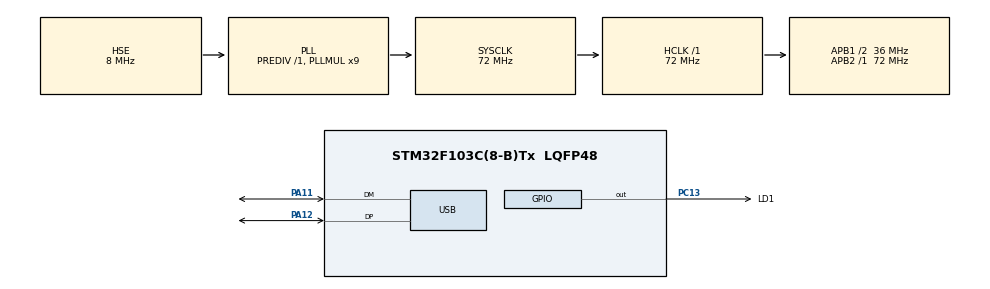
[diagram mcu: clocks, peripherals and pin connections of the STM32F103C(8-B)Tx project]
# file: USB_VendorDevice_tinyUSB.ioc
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Mcu.Family=STM32F1
Mcu.Name=STM32F103C(8-B)Tx
Mcu.Package=LQFP48
NVIC.PriorityGroup=NVIC_PRIORITYGROUP_4
NVIC.USB_HP_CAN1_TX_IRQn=true\:0\:0\:false\:false\:true\:true\:true
NVIC.USB_LP_CAN1_RX0_IRQn=true\:0\:0\:false\:false\:true\:true\:true
PA11.Mode=Device
PA11.Signal=USB_DM
PA12.Mode=Device
PA12.Signal=USB_DP
PA13.Mode=Serial_Wire
PA13.Signal=SYS_JTMS-SWDIO
PA14.Mode=Serial_Wire
PA14.Signal=SYS_JTCK-SWCLK
PC13-TAMPER-RTC.GPIO_Label=LD1
PC13-TAMPER-RTC.Signal=GPIO_Output
PD0-OSC_IN.Mode=HSE-External-Oscillator
PD0-OSC_IN.Signal=RCC_OSC_IN
PD1-OSC_OUT.Mode=HSE-External-Oscillator
PD1-OSC_OUT.Signal=RCC_OSC_OUT
ProjectManager.HeapSize=0x200
ProjectManager.StackSize=0x400
ProjectManager.TargetToolchain=STM32CubeIDE
RCC.AHBFreq_Value=72000000
RCC.APB1CLKDivider=RCC_HCLK_DIV2
RCC.APB1Freq_Value=36000000
RCC.APB1TimFreq_Value=72000000
RCC.APB2Freq_Value=72000000
RCC.APB2TimFreq_Value=72000000
RCC.HCLKFreq_Value=72000000
RCC.PLLMUL=RCC_PLL_MUL9
RCC.SYSCLKFreq_VALUE=72000000
RCC.SYSCLKSource=RCC_SYSCLKSOURCE_PLLCLK
RCC.USBFreq_Value=48000000
RCC.USBPrescaler=RCC_USBCLKSOURCE_PLL_DIV1_5
board=custom

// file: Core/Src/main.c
/* USER CODE BEGIN Header */
/**
  ******************************************************************************
  * @file           : main.c
  * @brief          : Main program body
  ******************************************************************************
  * @attention
  *
  * <h2><center>&copy; Copyright (c) 2021 STMicroelectronics.
  * All rights reserved.</center></h2>
  *
  * This software component is licensed by ST under BSD 3-Clause license,
  * the "License"; You may not use this file except in compliance with the
  * License. You may obtain a copy of the License at:
  *                        opensource.org/licenses/BSD-3-Clause
  *
  ******************************************************************************
  */
/* USER CODE END Header */
#include "main.h"
#include "usb.h"
#include "gpio.h"

/* USER CODE BEGIN Includes */
#include "usb_descriptors.h"
#include "tusb.h"
/* USER CODE END Includes */

void SystemClock_Config(void);
/* USER CODE BEGIN PFP */
void led_blinking_task(void);
void cdc_task(void);
void webserial_task(void);
/* USER CODE END PFP */

/* USER CODE BEGIN 0 */
#define URL  "example.tinyusb.org/webusb-serial/"

const tusb_desc_webusb_url_t desc_url =
{
  .bLength         = 3 + sizeof(URL) - 1,
  .bDescriptorType = 3, // WEBUSB URL type
  .bScheme         = 1, // 0: http, 1: https
  .url             = URL
};

static bool web_serial_connected = false;
/* USER CODE END 0 */

int main(void)
{

  /* MCU Configuration--------------------------------------------------------*/

  /* Reset of all peripherals, Initializes the Flash interface and the Systick. */
  HAL_Init();

  /* Configure the system clock */
  SystemClock_Config();

  /* Initialize all configured peripherals */
  MX_GPIO_Init();
  MX_USB_PCD_Init();
  /* USER CODE BEGIN 2 */
  tusb_init();
  /* USER CODE END 2 */

  /* Infinite loop */
  /* USER CODE BEGIN WHILE */
  while (1)
  {
	    tud_task(); // tinyusb device task
	    cdc_task();
	    webserial_task();
    /* USER CODE END WHILE */

  }
}

void SystemClock_Config(void)
{
  RCC_OscInitTypeDef RCC_OscInitStruct = {0};
  RCC_ClkInitTypeDef RCC_ClkInitStruct = {0};
  RCC_PeriphCLKInitTypeDef PeriphClkInit = {0};

  /** Initializes the RCC Oscillators according to the specified parameters
  * in the RCC_OscInitTypeDef structure.
  */
  RCC_OscInitStruct.OscillatorType = RCC_OSCILLATORTYPE_HSE;
  RCC_OscInitStruct.HSEState = RCC_HSE_ON;
  RCC_OscInitStruct.HSEPredivValue = RCC_HSE_PREDIV_DIV1;
  RCC_OscInitStruct.HSIState = RCC_HSI_ON;
  RCC_OscInitStruct.PLL.PLLState = RCC_PLL_ON;
  RCC_OscInitStruct.PLL.PLLSource = RCC_PLLSOURCE_HSE;
  RCC_OscInitStruct.PLL.PLLMUL = RCC_PLL_MUL9;
  if (HAL_RCC_OscConfig(&RCC_OscInitStruct) != HAL_OK)
  {
    Error_Handler();
  }
  /** Initializes the CPU, AHB and APB buses clocks
  */
  RCC_ClkInitStruct.ClockType = RCC_CLOCKTYPE_HCLK|RCC_CLOCKTYPE_SYSCLK
                              |RCC_CLOCKTYPE_PCLK1|RCC_CLOCKTYPE_PCLK2;
  RCC_ClkInitStruct.SYSCLKSource = RCC_SYSCLKSOURCE_PLLCLK;
  RCC_ClkInitStruct.AHBCLKDivider = RCC_SYSCLK_DIV1;
  RCC_ClkInitStruct.APB1CLKDivider = RCC_HCLK_DIV2;
  RCC_ClkInitStruct.APB2CLKDivider = RCC_HCLK_DIV1;

  if (HAL_RCC_ClockConfig(&RCC_ClkInitStruct, FLASH_LATENCY_2) != HAL_OK)
  {
    Error_Handler();
  }
  PeriphClkInit.PeriphClockSelection = RCC_PERIPHCLK_USB;
  PeriphClkInit.UsbClockSelection = RCC_USBCLKSOURCE_PLL_DIV1_5;
  if (HAL_RCCEx_PeriphCLKConfig(&PeriphClkInit) != HAL_OK)
  {
    Error_Handler();
  }
}

/* USER CODE BEGIN 4 */
// send characters to both CDC and WebUSB
void echo_all(uint8_t buf[], uint32_t count)
{
  // echo to web serial
  if ( web_serial_connected )
  {
    tud_vendor_write(buf, count);
  }

  // echo to cdc
  if ( tud_cdc_connected() )
  {
    for(uint32_t i=0; i<count; i++)
    {
      tud_cdc_write_char(buf[i]);

//      if ( buf[i] == '\r' ) tud_cdc_write_char('\n');
    }
    tud_cdc_write_flush();
  }
}

//--------------------------------------------------------------------+
// Device callbacks
//--------------------------------------------------------------------+

// Invoked when device is mounted
void tud_mount_cb(void)
{

}

// Invoked when device is unmounted
void tud_umount_cb(void)
{

}

// Invoked when usb bus is suspended
// remote_wakeup_en : if host allow us  to perform remote wakeup
// Within 7ms, device must draw an average of current less than 2.5 mA from bus
void tud_suspend_cb(bool remote_wakeup_en)
{
  (void) remote_wakeup_en;

}

// Invoked when usb bus is resumed
void tud_resume_cb(void)
{

}

//--------------------------------------------------------------------+
// WebUSB use vendor class
//--------------------------------------------------------------------+

// Invoked when a control transfer occurred on an interface of this class
// Driver response accordingly to the request and the transfer stage (setup/data/ack)
// return false to stall control endpoint (e.g unsupported request)
bool tud_vendor_control_xfer_cb(uint8_t rhport, uint8_t stage, tusb_control_request_t const * request)
{
  // nothing to with DATA & ACK stage
  if (stage != CONTROL_STAGE_SETUP) return true;

  switch (request->bmRequestType_bit.type)
  {
    case TUSB_REQ_TYPE_VENDOR:
      switch (request->bRequest)
      {
        case VENDOR_REQUEST_WEBUSB:
          // match vendor request in BOS descriptor
          // Get landing page url
          return tud_control_xfer(rhport, request, (void*)(uintptr_t) &desc_url, desc_url.bLength);

        case VENDOR_REQUEST_MICROSOFT:
          if ( request->wIndex == 7 )
          {
            // Get Microsoft OS 2.0 compatible descriptor
            uint16_t total_len;
            memcpy(&total_len, desc_ms_os_20+8, 2);

            return tud_control_xfer(rhport, request, (void*)(uintptr_t) desc_ms_os_20, total_len);
          }else
          {
            return false;
          }

        default: break;
      }
    break;

    case TUSB_REQ_TYPE_CLASS:
      if (request->bRequest == 0x22)
      {
        // Webserial simulate the CDC_REQUEST_SET_CONTROL_LINE_STATE (0x22) to connect and disconnect.
        web_serial_connected = (request->wValue != 0);

        // Always lit LED if connected
        if ( web_serial_connected )
        {

          tud_vendor_write_str("\r\nTinyUSB WebUSB device example\r\n");
        }else
        {

        }

        // response with status OK
        return tud_control_status(rhport, request);
      }
    break;

    default: break;
  }

  // stall unknown request
  return false;
}

void webserial_task(void)
{

    if ( tud_vendor_available() )
    {
      uint8_t buf[64];
      uint32_t count = tud_vendor_read(buf, sizeof(buf));

      // echo back to both web serial and cdc
      echo_all(buf, count);
    }

}

//--------------------------------------------------------------------+
// USB CDC
//--------------------------------------------------------------------+
void cdc_task(void)
{
  if ( tud_cdc_connected() )
  {
    // connected and there are data available
    if ( tud_cdc_available() )
    {
      uint8_t buf[64];

      uint32_t count = tud_cdc_read(buf, sizeof(buf));

      // echo back to both web serial and cdc
      echo_all(buf, count);
    }
  }
}

// Invoked when cdc when line state changed e.g connected/disconnected
void tud_cdc_line_state_cb(uint8_t itf, bool dtr, bool rts)
{
  (void) itf;

  // connected
  if ( dtr && rts )
  {
    // print initial message when connected
    tud_cdc_write_str("\r\nTinyUSB WebUSB device example\r\n");
  }
}

// Invoked when CDC interface received data from host
void tud_cdc_rx_cb(uint8_t itf)
{
  (void) itf;
}
/* USER CODE END 4 */

void Error_Handler(void)
{
  __disable_irq();
  while (1)
  {
  }
}

/************************ (C) COPYRIGHT STMicroelectronics *****END OF FILE****/
